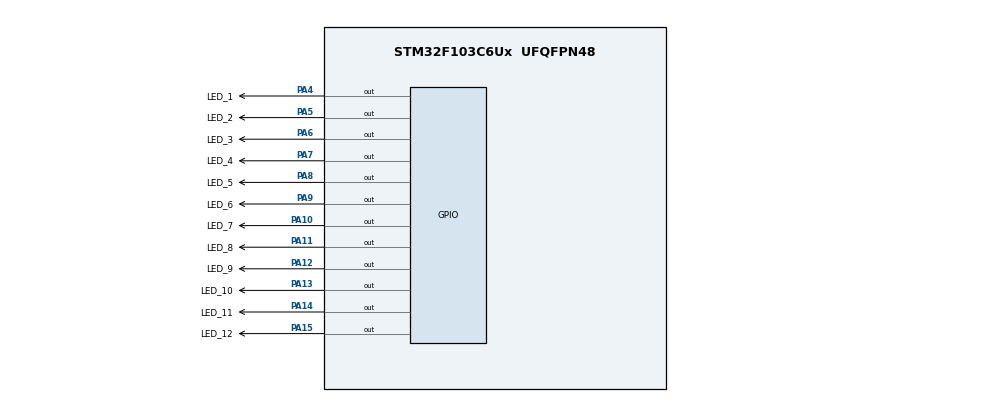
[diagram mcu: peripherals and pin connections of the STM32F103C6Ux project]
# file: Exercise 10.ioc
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Mcu.Family=STM32F1
Mcu.Name=STM32F103C6Ux
Mcu.Package=UFQFPN48
NVIC.PriorityGroup=NVIC_PRIORITYGROUP_4
PA10.GPIO_Label=LED_7
PA10.Signal=GPIO_Output
PA11.GPIO_Label=LED_8
PA11.Signal=GPIO_Output
PA12.GPIO_Label=LED_9
PA12.Signal=GPIO_Output
PA13.GPIO_Label=LED_10
PA13.Signal=GPIO_Output
PA14.GPIO_Label=LED_11
PA14.Signal=GPIO_Output
PA15.GPIO_Label=LED_12
PA15.Signal=GPIO_Output
PA4.GPIO_Label=LED_1
PA4.Signal=GPIO_Output
PA5.GPIO_Label=LED_2
PA5.Signal=GPIO_Output
PA6.GPIO_Label=LED_3
PA6.Signal=GPIO_Output
PA7.GPIO_Label=LED_4
PA7.Signal=GPIO_Output
PA8.GPIO_Label=LED_5
PA8.Signal=GPIO_Output
PA9.GPIO_Label=LED_6
PA9.Signal=GPIO_Output
ProjectManager.HeapSize=0x200
ProjectManager.StackSize=0x400
ProjectManager.TargetToolchain=STM32CubeIDE
RCC.APB1Freq_Value=8000000
RCC.APB2Freq_Value=8000000
VP_SYS_VS_ND.Mode=No_Debug
board=custom

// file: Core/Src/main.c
/* USER CODE BEGIN Header */
/**
  ******************************************************************************
  * @file           : main.c
  * @brief          : Main program body
  ******************************************************************************
  * @attention
  *
  * <h2><center>&copy; Copyright (c) 2022 STMicroelectronics.
  * All rights reserved.</center></h2>
  *
  * This software component is licensed by ST under BSD 3-Clause license,
  * the "License"; You may not use this file except in compliance with the
  * License. You may obtain a copy of the License at:
  *                        opensource.org/licenses/BSD-3-Clause
  *
  ******************************************************************************
  */
/* USER CODE END Header */
#include "main.h"

void SystemClock_Config(void);
static void MX_GPIO_Init(void);

void clearAllClock(){
HAL_GPIO_WritePin(GPIOA, GPIO_PIN_4, GPIO_PIN_SET);
HAL_GPIO_WritePin(GPIOA, GPIO_PIN_5, GPIO_PIN_SET);
HAL_GPIO_WritePin(GPIOA, GPIO_PIN_6, GPIO_PIN_SET);
HAL_GPIO_WritePin(GPIOA, GPIO_PIN_7, GPIO_PIN_SET);
HAL_GPIO_WritePin(GPIOA, GPIO_PIN_8, GPIO_PIN_SET);
HAL_GPIO_WritePin(GPIOA, GPIO_PIN_9, GPIO_PIN_SET);
HAL_GPIO_WritePin(GPIOA, GPIO_PIN_10, GPIO_PIN_SET);
HAL_GPIO_WritePin(GPIOA, GPIO_PIN_11, GPIO_PIN_SET);
HAL_GPIO_WritePin(GPIOA, GPIO_PIN_12, GPIO_PIN_SET);
HAL_GPIO_WritePin(GPIOA, GPIO_PIN_13, GPIO_PIN_SET);
HAL_GPIO_WritePin(GPIOA, GPIO_PIN_14, GPIO_PIN_SET);
HAL_GPIO_WritePin(GPIOA, GPIO_PIN_15, GPIO_PIN_SET);
}

void setNumberOnClock(int num){
	switch (num){
case 1:
HAL_GPIO_WritePin(GPIOA, GPIO_PIN_4, GPIO_PIN_RESET);
break; case 2:
HAL_GPIO_WritePin(GPIOA, GPIO_PIN_5, GPIO_PIN_RESET);
break; case 3:
HAL_GPIO_WritePin(GPIOA, GPIO_PIN_6, GPIO_PIN_RESET);
break; case 4:
HAL_GPIO_WritePin(GPIOA, GPIO_PIN_7, GPIO_PIN_RESET);
break; case 5:
HAL_GPIO_WritePin(GPIOA, GPIO_PIN_8, GPIO_PIN_RESET);
break; case 6:
HAL_GPIO_WritePin(GPIOA, GPIO_PIN_9, GPIO_PIN_RESET);
break; case 7:
HAL_GPIO_WritePin(GPIOA, GPIO_PIN_10, GPIO_PIN_RESET);
break; case 8:
HAL_GPIO_WritePin(GPIOA, GPIO_PIN_11, GPIO_PIN_RESET);
break; case 9:
HAL_GPIO_WritePin(GPIOA, GPIO_PIN_12, GPIO_PIN_RESET);
break; case 10:
HAL_GPIO_WritePin(GPIOA, GPIO_PIN_13, GPIO_PIN_RESET);
break; case 11:
HAL_GPIO_WritePin(GPIOA, GPIO_PIN_14, GPIO_PIN_RESET);
break; case 12:
HAL_GPIO_WritePin(GPIOA, GPIO_PIN_15, GPIO_PIN_RESET);
break;
}
}
void clearNumberOnClock(int num){
	switch (num){
case 1:
HAL_GPIO_WritePin(GPIOA, GPIO_PIN_4, GPIO_PIN_SET);
break; case 2:
HAL_GPIO_WritePin(GPIOA, GPIO_PIN_5, GPIO_PIN_SET);
break; case 3:
HAL_GPIO_WritePin(GPIOA, GPIO_PIN_6, GPIO_PIN_SET);
break; case 4:
HAL_GPIO_WritePin(GPIOA, GPIO_PIN_7, GPIO_PIN_SET);
break; case 5:
HAL_GPIO_WritePin(GPIOA, GPIO_PIN_8, GPIO_PIN_SET);
break; case 6:
HAL_GPIO_WritePin(GPIOA, GPIO_PIN_9, GPIO_PIN_SET);
break; case 7:
HAL_GPIO_WritePin(GPIOA, GPIO_PIN_10, GPIO_PIN_SET);
break; case 8:
HAL_GPIO_WritePin(GPIOA, GPIO_PIN_11, GPIO_PIN_SET);
break; case 9:
HAL_GPIO_WritePin(GPIOA, GPIO_PIN_12, GPIO_PIN_SET);
break; case 10:
HAL_GPIO_WritePin(GPIOA, GPIO_PIN_13, GPIO_PIN_SET);
break; case 11:
HAL_GPIO_WritePin(GPIOA, GPIO_PIN_14, GPIO_PIN_SET);
break; case 12:
HAL_GPIO_WritePin(GPIOA, GPIO_PIN_15, GPIO_PIN_SET);
break;
}
}
int main(void)
{

  /* MCU Configuration--------------------------------------------------------*/

  /* Reset of all peripherals, Initializes the Flash interface and the Systick. */
  HAL_Init();

  /* Configure the system clock */
  SystemClock_Config();

  /* Initialize all configured peripherals */
  MX_GPIO_Init();

  /* Infinite loop */
  /* USER CODE BEGIN WHILE */
  int i=0;
  int second =0;
  int minute =0;
  int hour =0;
  while (1)
  {
    /* USER CODE END WHILE */

	  i=i+1;
	  if(i==10){
	  second ++;
	  if(second==13) {
	  second =1;
	  if(minute!=12 && hour!=12){
		  clearNumberOnClock(12);
		  setNumberOnClock(second);
	  }
	  }
	  else {
	  setNumberOnClock(second);
	  if( (second -1)!= minute && (second -1)!=hour ) clearNumberOnClock(second -1);
	  }
	  //
	  if(second==12) {
		  minute ++;
	  if(minute==13) {
	  minute =1;
	  if(hour!=12){
		  clearNumberOnClock(12);
	  setNumberOnClock(minute);
	  }
	  }
	  else {
	  setNumberOnClock(minute);
	  if((minute -1)!=hour)clearNumberOnClock(minute -1); }
	  ///
	  if(minute==12){
		  hour ++;
	  if(hour==13){ hour =1;
	  setNumberOnClock(hour);
	  clearNumberOnClock(12); }
	  else { setNumberOnClock(hour); clearNumberOnClock(hour -1);
	  } }
	  }
	  i=0; }
	  HAL_Delay(10);
  }
}

void SystemClock_Config(void)
{
  RCC_OscInitTypeDef RCC_OscInitStruct = {0};
  RCC_ClkInitTypeDef RCC_ClkInitStruct = {0};

  /** Initializes the RCC Oscillators according to the specified parameters
  * in the RCC_OscInitTypeDef structure.
  */
  RCC_OscInitStruct.OscillatorType = RCC_OSCILLATORTYPE_HSI;
  RCC_OscInitStruct.HSIState = RCC_HSI_ON;
  RCC_OscInitStruct.HSICalibrationValue = RCC_HSICALIBRATION_DEFAULT;
  RCC_OscInitStruct.PLL.PLLState = RCC_PLL_NONE;
  if (HAL_RCC_OscConfig(&RCC_OscInitStruct) != HAL_OK)
  {
    Error_Handler();
  }
  /** Initializes the CPU, AHB and APB buses clocks
  */
  RCC_ClkInitStruct.ClockType = RCC_CLOCKTYPE_HCLK|RCC_CLOCKTYPE_SYSCLK
                              |RCC_CLOCKTYPE_PCLK1|RCC_CLOCKTYPE_PCLK2;
  RCC_ClkInitStruct.SYSCLKSource = RCC_SYSCLKSOURCE_HSI;
  RCC_ClkInitStruct.AHBCLKDivider = RCC_SYSCLK_DIV1;
  RCC_ClkInitStruct.APB1CLKDivider = RCC_HCLK_DIV1;
  RCC_ClkInitStruct.APB2CLKDivider = RCC_HCLK_DIV1;

  if (HAL_RCC_ClockConfig(&RCC_ClkInitStruct, FLASH_LATENCY_0) != HAL_OK)
  {
    Error_Handler();
  }
}

static void MX_GPIO_Init(void)
{
  GPIO_InitTypeDef GPIO_InitStruct = {0};

  /* GPIO Ports Clock Enable */
  __HAL_RCC_GPIOA_CLK_ENABLE();

  /*Configure GPIO pin Output Level */
  HAL_GPIO_WritePin(GPIOA, LED_1_Pin|LED_2_Pin|LED_3_Pin|LED_4_Pin
                          |LED_5_Pin|LED_6_Pin|LED_7_Pin|LED_8_Pin
                          |LED_9_Pin|LED_10_Pin|LED_11_Pin|LED_12_Pin, GPIO_PIN_RESET);

  /*Configure GPIO pins : LED_1_Pin LED_2_Pin LED_3_Pin LED_4_Pin
                           LED_5_Pin LED_6_Pin LED_7_Pin LED_8_Pin
                           LED_9_Pin LED_10_Pin LED_11_Pin LED_12_Pin */
  GPIO_InitStruct.Pin = LED_1_Pin|LED_2_Pin|LED_3_Pin|LED_4_Pin
                          |LED_5_Pin|LED_6_Pin|LED_7_Pin|LED_8_Pin
                          |LED_9_Pin|LED_10_Pin|LED_11_Pin|LED_12_Pin;
  GPIO_InitStruct.Mode = GPIO_MODE_OUTPUT_PP;
  GPIO_InitStruct.Pull = GPIO_NOPULL;
  GPIO_InitStruct.Speed = GPIO_SPEED_FREQ_LOW;
  HAL_GPIO_Init(GPIOA, &GPIO_InitStruct);

}

void Error_Handler(void)
{
  __disable_irq();
  while (1)
  {
  }
}

/************************ (C) COPYRIGHT STMicroelectronics *****END OF FILE****/
